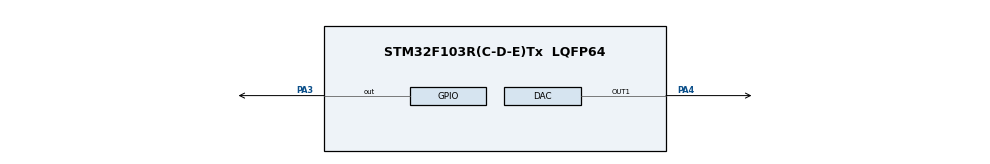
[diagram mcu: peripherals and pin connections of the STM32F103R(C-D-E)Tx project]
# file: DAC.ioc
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DAC.DAC_Trigger=DAC_TRIGGER_NONE
Mcu.Family=STM32F1
Mcu.Name=STM32F103R(C-D-E)Tx
Mcu.Package=LQFP64
NVIC.PriorityGroup=NVIC_PRIORITYGROUP_4
PA13.Mode=JTAG_5_pins
PA13.Signal=SYS_JTMS-SWDIO
PA14.Mode=JTAG_5_pins
PA14.Signal=SYS_JTCK-SWCLK
PA15.Mode=JTAG_5_pins
PA15.Signal=SYS_JTDI
PA3.Signal=GPIO_Output
PA4.Signal=COMP_DAC1_group
PB3.Mode=JTAG_5_pins
PB3.Signal=SYS_JTDO-TRACESWO
PB4.Mode=JTAG_5_pins
PB4.Signal=SYS_NJTRST
PD0-OSC_IN.Mode=HSE-External-Oscillator
PD0-OSC_IN.Signal=RCC_OSC_IN
PD1-OSC_OUT.Mode=HSE-External-Oscillator
PD1-OSC_OUT.Signal=RCC_OSC_OUT
ProjectManager.HeapSize=0x200
ProjectManager.StackSize=0x400
ProjectManager.TargetToolchain=MDK-ARM V5.27
RCC.AHBFreq_Value=36000000
RCC.APB1Freq_Value=36000000
RCC.APB1TimFreq_Value=36000000
RCC.APB2Freq_Value=36000000
RCC.APB2TimFreq_Value=36000000
RCC.HCLKFreq_Value=36000000
RCC.PLLMUL=RCC_PLL_MUL9
RCC.SYSCLKFreq_VALUE=36000000
RCC.SYSCLKSource=RCC_SYSCLKSOURCE_PLLCLK
RCC.USBFreq_Value=36000000
SH.COMP_DAC1_group.0=DAC_OUT1,DAC_OUT1
board=custom

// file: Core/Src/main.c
/* USER CODE BEGIN Header */
/**
  ******************************************************************************
  * @file           : main.c
  * @brief          : Main program body
  ******************************************************************************
  * @attention
  *
  * <h2><center>&copy; Copyright (c) 2021 STMicroelectronics.
  * All rights reserved.</center></h2>
  *
  * This software component is licensed by ST under BSD 3-Clause license,
  * the "License"; You may not use this file except in compliance with the
  * License. You may obtain a copy of the License at:
  *                        opensource.org/licenses/BSD-3-Clause
  *
  ******************************************************************************
  */
/* USER CODE END Header */
#include "main.h"

/* USER CODE BEGIN PD */
	/* Lookup tables for Sine and Sawtooth waves */
	const uint8_t Sine_Lookup[64] = {0x19,0x1b,0x1e,0x20,0x23,0x25,0x27,0x29, 0x2b,0x2c,0x2e,0x2f,0x30,0x31,0x32,0x32, 0x32,0x32, 0x32,0x31,0x30,0x2f,0x2e,0x2c, 0x2b,0x29,0x27,0x25,0x23,0x20,0x1e,0x1b, 0x19,0x17, 0x14,0x12,0xf, 0xd,0xb,0x9, 0x7,0x6,0x4,0x3,0x2,0x1,0x0,0x0, 0x0,0x0,0x0,0x1,0x2,0x3,0x4,0x6, 0x7,0x9,0xb,0xd,0xf,0x12,0x14,0x17};
	const uint8_t Saw_Lookup[] = {0x01,0x02,0x03,0x04,0x05,0x06,0x07,0x08,0x09,0x0A,0x0B,0x0C,0x0D,0x0E,0x0F};
/* USER CODE END PD */

void SystemClock_Config(void);
static void MX_GPIO_Init(void);
static void MX_DAC_Init(void);

int main(void)
{

  /* MCU Configuration--------------------------------------------------------*/

  /* Reset of all peripherals, Initializes the Flash interface and the Systick. */

  LL_APB2_GRP1_EnableClock(LL_APB2_GRP1_PERIPH_AFIO);
  LL_APB1_GRP1_EnableClock(LL_APB1_GRP1_PERIPH_PWR);

  NVIC_SetPriorityGrouping(NVIC_PRIORITYGROUP_4);

  /* System interrupt init*/

  /** ENABLE: Full SWJ (JTAG-DP + SW-DP): Reset State
  */
  LL_GPIO_AF_EnableRemap_SWJ();

  /* Configure the system clock */
  SystemClock_Config();

  /* Initialize all configured peripherals */
  MX_GPIO_Init();
  MX_DAC_Init();
  /* USER CODE BEGIN 2 */
	LL_DAC_Enable(DAC, LL_DAC_CHANNEL_1);			//Enable DAC
	float value = 0.2;
	uint16_t var;
	int i = 0;
  /* USER CODE END 2 */

  /* Infinite loop */
  while (1)
  {

    /* USER CODE BEGIN 3 */

	////square wave***
	LL_DAC_ConvertData12RightAligned(DAC, LL_DAC_CHANNEL_1, 0xFFF);
	LL_mDelay(10);
	LL_DAC_ConvertData12RightAligned(DAC, LL_DAC_CHANNEL_1, 0x000);
	LL_mDelay(10);

  ////stair wave
//		var = (uint16_t) value*(0xff0)/3.3;
//		LL_DAC_ConvertData12RightAligned(DAC, LL_DAC_CHANNEL_1, var);
//		value += 0.1;
////		LL_mDelay(1);
//		if(value>3.3)
//			value = 0.1;

  ////stair wave2
//		var = (uint16_t) i*(0xff0)/15;
//		LL_DAC_ConvertData12RightAligned(DAC, LL_DAC_CHANNEL_1, var);
//		i++;
////		LL_mDelay(1);
//		if(i>15)
//			i = 0;

			////saw tooth wave***
//				LL_DAC_ConvertData12RightAligned(DAC, LL_DAC_CHANNEL_1, Saw_Lookup[i++]*(0xfff )/Saw_Lookup[sizeof(Saw_Lookup)-1]);
//				if(i>= sizeof(Saw_Lookup))
//		   	i = 0;
//
	////sine wave***
//				LL_DAC_ConvertData12RightAligned(DAC, LL_DAC_CHANNEL_1, Sine_Lookup[i++]*(0xfff )/0x32);
//				if(i>= sizeof(Sine_Lookup))
//				i = 0;

	////(software trig for)auto-generated triangular wave***
			//LL_DAC_TrigSWConversion(DAC, LL_DAC_CHANNEL_1);

  }
  /* USER CODE END 3 */
}

void SystemClock_Config(void)
{
  LL_FLASH_SetLatency(LL_FLASH_LATENCY_1);
  while(LL_FLASH_GetLatency()!= LL_FLASH_LATENCY_1)
  {
  }
  LL_RCC_HSI_SetCalibTrimming(16);
  LL_RCC_HSI_Enable();

   /* Wait till HSI is ready */
  while(LL_RCC_HSI_IsReady() != 1)
  {

  }
  LL_RCC_PLL_ConfigDomain_SYS(LL_RCC_PLLSOURCE_HSI_DIV_2, LL_RCC_PLL_MUL_9);
  LL_RCC_PLL_Enable();

   /* Wait till PLL is ready */
  while(LL_RCC_PLL_IsReady() != 1)
  {

  }
  LL_RCC_SetAHBPrescaler(LL_RCC_SYSCLK_DIV_1);
  LL_RCC_SetAPB1Prescaler(LL_RCC_APB1_DIV_1);
  LL_RCC_SetAPB2Prescaler(LL_RCC_APB2_DIV_1);
  LL_RCC_SetSysClkSource(LL_RCC_SYS_CLKSOURCE_PLL);

   /* Wait till System clock is ready */
  while(LL_RCC_GetSysClkSource() != LL_RCC_SYS_CLKSOURCE_STATUS_PLL)
  {

  }
  LL_Init1msTick(36000000);
  LL_SetSystemCoreClock(36000000);
}

static void MX_DAC_Init(void)
{

  LL_DAC_InitTypeDef DAC_InitStruct = {0};

  LL_GPIO_InitTypeDef GPIO_InitStruct = {0};

  /* Peripheral clock enable */
  LL_APB1_GRP1_EnableClock(LL_APB1_GRP1_PERIPH_DAC1);

  LL_APB2_GRP1_EnableClock(LL_APB2_GRP1_PERIPH_GPIOA);
  /**DAC GPIO Configuration
  PA4   ------> DAC_OUT1
  */
  GPIO_InitStruct.Pin = LL_GPIO_PIN_4;
  GPIO_InitStruct.Mode = LL_GPIO_MODE_ANALOG;
  LL_GPIO_Init(GPIOA, &GPIO_InitStruct);

  /** DAC channel OUT1 config
  */
  DAC_InitStruct.TriggerSource = LL_DAC_TRIG_SOFTWARE;
  DAC_InitStruct.WaveAutoGeneration = LL_DAC_WAVE_AUTO_GENERATION_NONE;
  DAC_InitStruct.OutputBuffer = 	LL_DAC_OUTPUT_BUFFER_DISABLE;

  LL_DAC_Init(DAC, LL_DAC_CHANNEL_1, &DAC_InitStruct);
  LL_DAC_DisableTrigger(DAC, LL_DAC_CHANNEL_1);

}

static void MX_GPIO_Init(void)
{
  LL_GPIO_InitTypeDef GPIO_InitStruct = {0};

  /* GPIO Ports Clock Enable */
  LL_APB2_GRP1_EnableClock(LL_APB2_GRP1_PERIPH_GPIOD);
  LL_APB2_GRP1_EnableClock(LL_APB2_GRP1_PERIPH_GPIOA);
  LL_APB2_GRP1_EnableClock(LL_APB2_GRP1_PERIPH_GPIOB);

  /**/
  LL_GPIO_ResetOutputPin(GPIOA, LL_GPIO_PIN_3);

  /**/
  GPIO_InitStruct.Pin = LL_GPIO_PIN_3;
  GPIO_InitStruct.Mode = LL_GPIO_MODE_OUTPUT;
  GPIO_InitStruct.Speed = LL_GPIO_SPEED_FREQ_LOW;
  GPIO_InitStruct.OutputType = LL_GPIO_OUTPUT_PUSHPULL;
  LL_GPIO_Init(GPIOA, &GPIO_InitStruct);

}

void Error_Handler(void)
{
}

/************************ (C) COPYRIGHT STMicroelectronics *****END OF FILE****/
